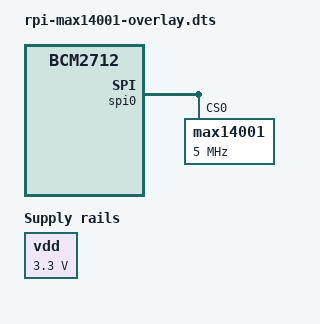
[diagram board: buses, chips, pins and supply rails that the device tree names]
// SPDX-License-Identifier: GPL-2.0-only
/*
 * Overlay for the MAX14001 ADC
 *
 * Copyright (c) 2025 Marilene Andrade Garcia <marilene.agarcia@gmail.com>
 *
 * Datasheet: https://www.analog.com/media/en/technical-documentation/data-sheets/MAX14001-MAX14002.pdf
 */

/dts-v1/;
/plugin/;

/ {
	compatible = "brcm,bcm2712";

	vdd: fixedregulator@0 {
		compatible = "regulator-fixed";
		regulator-name = "fixed-supply";
		regulator-min-microvolt = <3300000>;
		regulator-max-microvolt = <3300000>;
		regulator-boot-on;
		enable-active-high;
		status = "okay";
	};
};

&spi0 {
    status = "okay";
	max14001: max14001@0 {
		compatible = "max14001";
		reg = <0>;
		spi-max-frequency = <5000000>;
		status = "okay";
	};
};
